# SPC1169 register map
File version: 2022071043481212
CPU: cm4 r1p0, little endian, no MPU, FPU, 4 interrupt priority bits
Registers are 32-bit, read-write, reset 0x0 unless marked. A register's access mark holds for its fields unless they carry their own. Offsets are from the block's base; [hi:lo] are bit positions; {n}, {i} and the like mark numbered series; 'fields as' and 'values as' point back to an identical list.

## SPI0
Base 0x40001500
Same registers: SPI1 0x40001700
0x00 SPIDATA
  [31:0] VAL — Data to be written to the TXFIFO or read from the RXFIFO
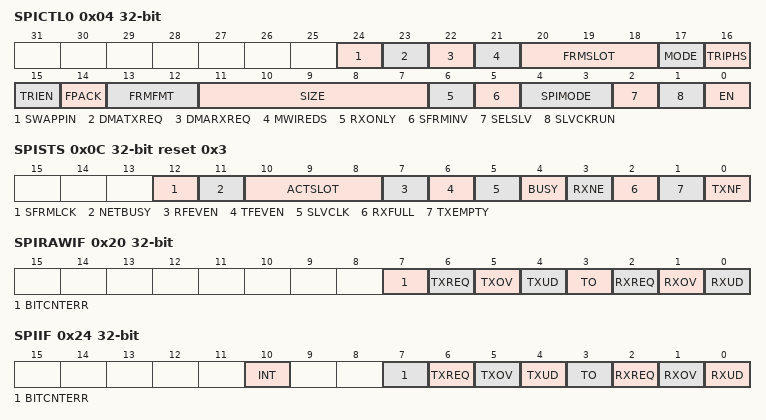
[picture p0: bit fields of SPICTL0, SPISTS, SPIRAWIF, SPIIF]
0x04 SPICTL0 — SPI Control Register 0
  [24] SWAPPIN — Swap MOSI and MISO pin
    0=ORIGINAL_FUNCTION (Trailing bytes are handled by CPU.); 1=SWAP_FUNCTION (Trailing bytes are handled by DMA, invaid when FIFO packing mode enabled.)
  [23] DMATXREQ — DMA Transmit Service Request Enable
    0=DISABLE; 1=ENABLE
  [22] DMARXREQ — DMA Receive Service Request Enable
    0=DISABLE; 1=ENABLE
  [21] MWIREDS — Microwire Transmit Command Data Size. Only used for MWIRE.
    0=SIZE_8BIT (8-bit command words are transmitted.); 1=SIZE_16BIT (16-bit command words are transmitted.)
  [20:18] FRMSLOT — Frame Slot. Only used for Network mode. Specifies the number of time slots per frame (the actual number of time slots is this field + 1, so 1 to 8 time slots can be specified).
  [17] MODE — Mode Select
    0=SPI (Normal SPI mode.); 1=NETWORK (Network mode, worked with PSP format.)
  [16] TRIPHS — STXD Tri-state Enable On Last Phase
    0=ON_MIDDLE_LSB (STXD is tri-stated 1/2 clock cycle after the beginning of the LSB. Note: Must be 0b0 for SPI/MWIRE frame format.); 1=ON_END_LSB (STXD is tri-stated on the clock edge that ends the LSB.)
  [15] TRIEN — STXD Tri-State Enable
    0=DISABLE (STXD is not tri-stated); 1=ENABLE (STXD is tri-stated when not transmitting data)
  [14] FPACK — FIFO Packing Enable
    0=DISABLE (FIFO packing mode disabled); 1=ENABLE (FIFO packing mode enabled)
  [13:12] FRMFMT — Frame Format
    0=SPI (Motorola Serial Peripheral Interface (SPI)); 1=SSP (Texas Instruments Synchronous Serial Protocol(SSP)); 2=MWIRE (National Semiconductor Microwire); 3=PSP (Programmable Serial Protocol (PSP))
  [11:7] SIZE — Data Size Select
  [6] RXONLY — Receive Without Transmit. Only used for Slave mode.
    0=DISABLE (Transmit/Receive mode); 1=ENABLE (Receive without Transmit mode)
  [5] SFRMINV — Invert Frame Signal
    0=DISABLE (SFRM polarity is determined by the PSP polarity bit); 1=ENABLE (SFRM is inverted from normal SFRM (as defined by the PSP polarity bit))
  [4:3] SPIMODE — SPI Clock Mode Select (Only used for SPI frame format)
    0=PHS_POL_00 (PHS = 0, POL = 0); 1=PHS_POL_01 (PHS = 0, POL = 1); 2=PHS_POL_10 (PHS = 1, POL = 0); 3=PHS_POL_11 (PHS = 1, POL = 1)
  [2] SELSLV — Select Slave Mode
    0=DISABLE (Master mode, SPI port drives SFRM & SCLK); 1=ENABLE (Slave mode, SPI port receives SFRM & SCLK)
  [1] SLVCKRUN — Slave Clock Free Running. Only used for Slave mode.
    0=DISABLE (Clock input to SCLK is only active during data transfers); 1=ENABLE (Clock input to SCLK is continuously running. Must be enabled for SPI format.)
  [0] EN — Synchronous Serial Port Enable
    0=DISABLE (Disable SPI); 1=ENABLE (Enable SPI)
0x08 SPICTL1 — SPI Control Register 1
  [0] SFRMLCK — SFRM Lock Enable. Only valid for SPI format, Master mode
    0=DISABLE (Disable SFRM lock status); 1=ENABLE (Enable SFRM lock function. SFRM will be locked at active level after SPI start send data, then need manually clear this bit to release locked SFRM to normal status.)
0x0C SPISTS ro reset 0x3 — SPI Status Register
  [12] SFRMLCK — SFRM Locked. Only valid for SPI format
    0=NOT_LOCK (SFRM not locked); 1=LOCKED (SFRM locked)
  [11] NETBUSY — Network mode busy
    0=NETWORK_IDLE (SPI port is in network mode and no frame is currently active); 1=NETWORK_BUSY (SPI port is in network mode and a frame is currently active)
  [10:8] ACTSLOT — Current active time slot. Because of synchronization between the SPI port's SCLK domain and an internal bus clock domain, the value in this field becomes stable between the beginning and end of the currently active time slot.
    {v}=SLOT_{v} (Time slot {v} is active) (v=0..7)
  [7] RFEVEN — RXFIFO Even Sample Status. This bit must be looked at only when FIFO Packing is enabled. Otherwise, this bit = 0.
    0=ODD_SAMPLES (RXFIFO entry has odd samples); 1=EVEN_SAMPLES (RXFIFO entry has even sample)
  [6] TFEVEN — TXFIFO Even Sample Status. This bit must be looked at only when FIFO Packing is enabled. Otherwise, this bit = 0.
    0=ODD_SAMPLES (TXFIFO entry has a odd number of samples); 1=EVEN_SAMPLES (TXFIFO entry has an even number of samples)
  [5] SLVCLK — Clock Synchronization Status. Software need only read this bit when the SPIx port is a slave or when the SPIx port is in the special FIFO test mode. Software should wait until this bit is cleared before allowing an external device to assert the external SFRM or SCLK signals.
    0=READY (The SPIx port is ready for slave clock operations.); 1=BUSY (The SPIx port is currently busy synchronizing slave mode signals.)
  [4] BUSY — SPI busy
    0=PORT_IDLE (SPIx port is idle or disabled.); 1=PORT_BUSY (SPIx port is currently transmitting or receiving framed data.)
  [3] RXNE — Receive FIFO Not Empty
    0=EMPTY (RXFIFO is empty); 1=NOT_EMPTY (RXFIFO is not empty)
  [2] RXFULL — Receive FIFO full
    0=NOT_FULL (Receive FIFO contains empty locations); 1=FULL (Receive FIFO is completely full)
  [1] TXEMPTY — Transmit FIFO Not Full
    0=NOT_EMPTY (Transmit FIFO contains one ore more data entries); 1=EMPTY (Transmit FIFO is completely empty. But there may be still data in the transmit shift out register and the transmit is going on.)
  [0] TXNF — Transmit FIFO Not Full
    0=FULL (TXFIFO is full); 1=NOT_FULL (TXFIFO is not full)
0x10 SPIRFLVL ro — SPI Receive FIFO Level Register
  [4:0] VAL — Number of valid data entries in the receive FIFO
0x14 SPITFLVL ro — SPI Transmit FIFO Level Register
  [4:0] VAL — Number of valid data entries in the transmit FIFO
0x18 SPIRFTH — SPI Receive FIFO Threshold Register
  [3:0] VAL — Trigger receive data available interrupt when SSPRFLVL>SSPTRFTH
0x1C SPITFTH — SPI Transmit FIFO Threshold Register
  [3:0] VAL — Trigger transmit data request interrupt when SSPTFLVL<=SSPTFTH
0x20 SPIRAWIF ro — SPI Raw Interrupt Flag Register
  [7] BITCNTERR — Bit Count Error Interrupt Flag
    0=NOT_OCCUR (Bit count error not occurred); 1=OCCUR (Bit count error occurred)
  [6] TXREQ — Transmit FIFO Service Request Interrupt Flag
    0=NOT_OCCUR (TXFIFO not trig threshold); 1=OCCUR (TXFIFO trig threshold)
  [5] TXOV — Transmit FIFO overrun interrupt Flag
    0=NOT_OCCUR (TXFIFO overrun not occurred); 1=OCCUR (TXFIFO overrun occurred)
  [4] TXUD — Transmit FIFO Underrun Interrupt Flag
    0=NOT_OCCUR (TXFIFO underrun not occurred); 1=OCCUR (TXFIFO underrun occurred)
  [3] TO — Receiver Timeout Interrupt Flag
    0=NOT_OCCUR (Timeout not occurred); 1=OCCUR (Timeout occurred)
  [2] RXREQ — Receive FIFO Service Request Interrupt Flag
    0=NOT_OCCUR (RXFIFO not trig threshold); 1=OCCUR (RXFIFO trig threshold)
  [1] RXOV — Receive FIFO Overrun Interrupt Flag
    0=NOT_OCCUR (RXFIFO overrun not occurred); 1=OCCUR (RXFIFO overrun occurred)
  [0] RXUD — Receive FIFO underrun interrupt Flag
    0=NOT_OCCUR (RXFIFO underrun not occurred); 1=OCCUR (RXFIFO underrun occurred)
0x24 SPIIF ro — SPI Interrupt Flag Register
  [10] INT — Global interrupt flag
    0=NOT_OCCUR (No interrupt occurred); 1=OCCUR (Some Interrupt occurred)
  [7] BITCNTERR — Bit Count Error Interrupt Flag
    values as SPIRAWIF.BITCNTERR
  [6] TXREQ — Transmit FIFO Service Request Interrupt Flag
    values as SPIRAWIF.TXREQ
  [5] TXOV — Transmit FIFO overrun interrupt Flag
    values as SPIRAWIF.TXOV
  [4] TXUD — Transmit FIFO Underrun Interrupt Flag
    values as SPIRAWIF.TXUD
  [3] TO — Receiver Timeout Interrupt Flag
    values as SPIRAWIF.TO
  [2] RXREQ — Receive FIFO Service Request Interrupt Flag
    values as SPIRAWIF.RXREQ
  [1] RXOV — Receive FIFO Overrun Interrupt Flag
    values as SPIRAWIF.RXOV
  [0] RXUD — Receive FIFO underrun interrupt Flag
    values as SPIRAWIF.RXUD
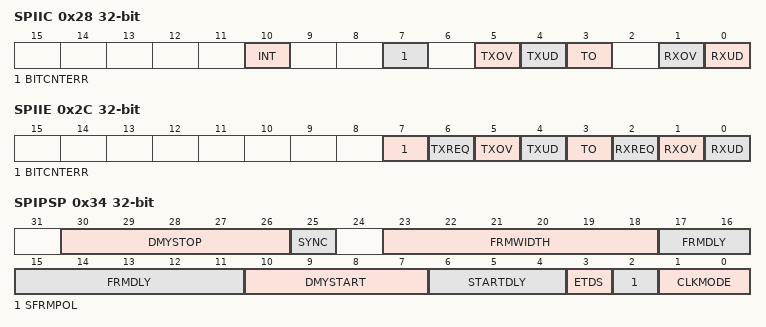
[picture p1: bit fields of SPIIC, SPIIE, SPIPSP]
0x28 SPIIC — SPI Interrupt Clear Register
  [all] fields
    0=NO_EFFECT (Write 0 has no effect and always reads back 0); 1=CLEAR (Write 1 clears the flag. This bit is self cleared.)
  [10] INT — Global Interrupt Clear
  [7] BITCNTERR — Bit Count Error Interrupt Clear
  [5] TXOV — Transmit FIFO overrun interrupt Clear
  [4] TXUD — Transmit FIFO Underrun Interrupt Clear
  [3] TO — Receiver Timeout Interrupt Clear
  [1] RXOV — Receive FIFO Overrun Interrupt Clear
  [0] RXUD — Receive FIFO underrun interrupt Clear
0x2C SPIIE — SPI Interrupt Enable Register
  [all] fields
    0=DISABLE; 1=ENABLE
  [7] BITCNTERR — Bit Count Error Interrupt Enable
  [6] TXREQ — Transmit FIFO Service Request Interrupt Enable
  [5] TXOV — Transmit FIFO overrun interrupt enable
  [4] TXUD — Transmit FIFO Underrun Interrupt Enable
  [3] TO — Receiver Timeout Interrupt Enable
  [2] RXREQ — Receive FIFO Service Request Interrupt Enable
  [1] RXOV — Receive FIFO Overrun Interrupt Enable
  [0] RXUD — Receive FIFO underrun interrupt enable
0x30 SPITO — SPI Time Out Register
  [23:0] VAL — Timeout interval defined as 2^VAL+1 SPI clock (CLK_SPI)
0x34 SPIPSP — SPI Programmable Serial Protocol Register
  [30:26] DMYSTOP — Dummy stop. Only used in PSP frame format. Do not use in PSP Network mode, and must be 0 when worked in Network mode.
  [25] SYNC — Frame Sync Relative Timing Bit. Only used in PSP frame format.
    0=AFTER_DMYSTOP (Next frame is asserted after the end of the DMYSTOP timing.); 1=AFTER_LSB (Next frame is asserted with the LSB of the previous frame.)
  [23:18] FRMWIDTH — Serial Frame Width. Only used in PSP frame format. Only valid when SPI in Master mode.
  [17:11] FRMDLY — Serial Frame Delay. Only used in PSP frame format. Do not use in PSP Network mode, and must be 0 when worked in Network mode.
  [10:7] DMYSTART — Dummy Start. Only used in PSP frame format. Do not use in PSP Network mode, and must be 0 when worked in Network mode.
  [6:4] STARTDLY — Start Delay. Only used in PSP frame format. Do not use in PSP Network mode, and must be 0 when worked in Network mode.
  [3] ETDS — End Of Transfer Data State. Only used in PSP frame format.
    0=LOW (Level low); 1=LSB_VALUE (Level of LSB value)
  [2] SFRMPOL — Serial Frame Polarity
    0=ACTIVE_LOW (SFRM is active low (0b0)); 1=ACTIVE_HIGH (SFRM is active high (0b1))
  [1:0] CLKMODE — Serial Bit-rate Clock Mode. Only used in PSP frame format.
    0=DF_SR_IL (Data Driven (Falling), Data Sampled (Rising), Idle State (Low)); 1=DR_SF_IL (Data Driven (Rising), Data Sampled (Falling), Idle State (Low)); 2=DR_SF_IH (Data Driven (Rising), Data Sampled (Falling), Idle State (High)); 3=DF_SR_IH (Data Driven (Falling), Data Sampled (Rising), Idle State (High))
0x40 SPITCTL — SPI Test Control Register
  [0] LOOP — Loopback mode
    0=DISABLE (Normal serial port operation is enabled.); 1=ENABLE (Output of TX serial shifter is internally connected to input of RX serial shifter.)
0x44 SPIBDCNT — SPI Baud Count Register
  [15:0] VAL — SPI baud rate will be SPI clock / (SSPBDCNT+1)
0x48 SPIREGKEY reset 0x1ACCE551 — SPI Register Write-Allow Key Register
  [31:0] KEY — Write 0x1ACCE551 to unlock protected SPI registers
